AUTOSAR XML (schema 4-2-2)
package /STELLANTIS/EPT/ASWCs
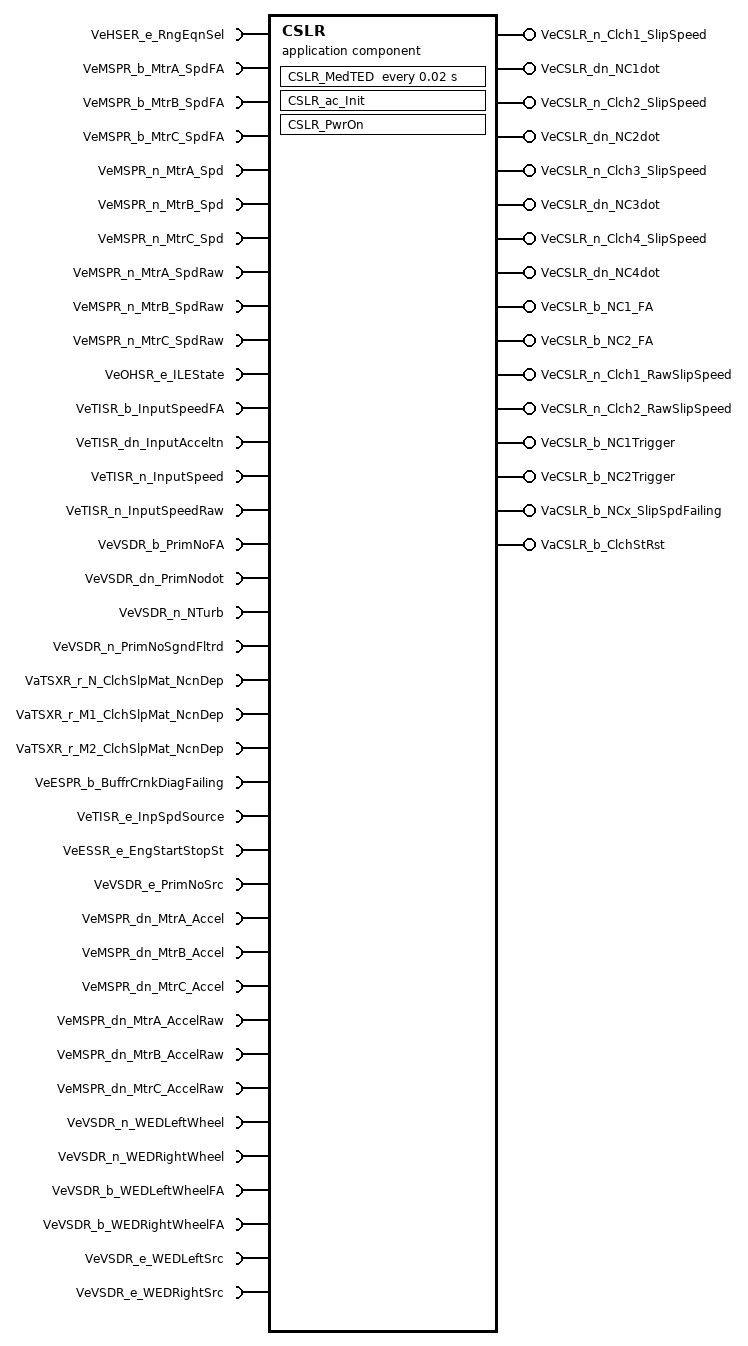
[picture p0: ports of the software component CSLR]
  application sw component type CSLR
    38 x require port:
      VeHSER_e_RngEqnSel: nonqueued-receiver-com-spec{data-element=Value, init-value=CeHSER_e_UseNeutralEqn}, required-interface=VeHSER_e_RngEqnSel
      VeMSPR_b_MtrA_SpdFA: nonqueued-receiver-com-spec{data-element=Value, init-value=0}, required-interface=VeMSPR_b_MtrA_SpdFA
      VeMSPR_b_MtrB_SpdFA: nonqueued-receiver-com-spec{data-element=Value, init-value=0}, required-interface=VeMSPR_b_MtrB_SpdFA
      VeMSPR_b_MtrC_SpdFA: nonqueued-receiver-com-spec{data-element=Value, init-value=0}, required-interface=VeMSPR_b_MtrC_SpdFA
      VeMSPR_n_MtrA_Spd: nonqueued-receiver-com-spec{data-element=Value, init-value=0}, required-interface=VeMSPR_n_MtrA_Spd
      VeMSPR_n_MtrB_Spd: nonqueued-receiver-com-spec{data-element=Value, init-value=0}, required-interface=VeMSPR_n_MtrB_Spd
      VeMSPR_n_MtrC_Spd: nonqueued-receiver-com-spec{data-element=Value, init-value=0}, required-interface=VeMSPR_n_MtrC_Spd
      VeMSPR_n_MtrA_SpdRaw: nonqueued-receiver-com-spec{data-element=Value, init-value=0}, required-interface=VeMSPR_n_MtrA_SpdRaw
      VeMSPR_n_MtrB_SpdRaw: nonqueued-receiver-com-spec{data-element=Value, init-value=0}, required-interface=VeMSPR_n_MtrB_SpdRaw
      VeMSPR_n_MtrC_SpdRaw: nonqueued-receiver-com-spec{data-element=Value, init-value=0}, required-interface=VeMSPR_n_MtrC_SpdRaw
      VeOHSR_e_ILEState: nonqueued-receiver-com-spec{data-element=Value, init-value=CeOHSR_e_NeutralState}, required-interface=VeOHSR_e_ILEState
      VeTISR_b_InputSpeedFA: nonqueued-receiver-com-spec{data-element=Value, init-value=0}, required-interface=VeTISR_b_InputSpeedFA
      VeTISR_dn_InputAcceltn: nonqueued-receiver-com-spec{data-element=Value, init-value=0}, required-interface=VeTISR_dn_InputAcceltn
      VeTISR_n_InputSpeed: nonqueued-receiver-com-spec{data-element=Value, init-value=0}, required-interface=VeTISR_n_InputSpeed
      VeTISR_n_InputSpeedRaw: nonqueued-receiver-com-spec{data-element=Value, init-value=0}, required-interface=VeTISR_n_InputSpeedRaw
      VeVSDR_b_PrimNoFA: nonqueued-receiver-com-spec{data-element=Value, init-value=0}, required-interface=VeVSDR_b_PrimNoFA
      VeVSDR_dn_PrimNodot: nonqueued-receiver-com-spec{data-element=Value, init-value=0}, required-interface=VeVSDR_dn_PrimNodot
      VeVSDR_n_NTurb: nonqueued-receiver-com-spec{data-element=Value, init-value=0}, required-interface=VeVSDR_n_NTurb
      VeVSDR_n_PrimNoSgndFltrd: nonqueued-receiver-com-spec{data-element=Value, init-value=0}, required-interface=VeVSDR_n_PrimNoSgndFltrd
      VaTSXR_r_N_ClchSlpMat_NcnDep: nonqueued-receiver-com-spec{data-element=Value, init-value=32 x 0}, required-interface=VaTSXR_r_N_ClchSlpMat_NcnDep
      VaTSXR_r_M1_ClchSlpMat_NcnDep: nonqueued-receiver-com-spec{data-element=Value, init-value=32 x 0}, required-interface=VaTSXR_r_M1_ClchSlpMat_NcnDep
      VaTSXR_r_M2_ClchSlpMat_NcnDep: nonqueued-receiver-com-spec{data-element=Value, init-value=32 x 0}, required-interface=VaTSXR_r_M2_ClchSlpMat_NcnDep
      VeESPR_b_BuffrCrnkDiagFailing: nonqueued-receiver-com-spec{data-element=Value, init-value=0}, required-interface=VeESPR_b_BuffrCrnkDiagFailing
      VeTISR_e_InpSpdSource: nonqueued-receiver-com-spec{data-element=Value, init-value=CeTISR_e_EngSpeedFromCAN}, required-interface=VeTISR_e_InpSpdSource
      VeESSR_e_EngStartStopSt: nonqueued-receiver-com-spec{data-element=Value, init-value=CeESSR_e_EngOff}, required-interface=VeESSR_e_EngStartStopSt
      VeVSDR_e_PrimNoSrc: nonqueued-receiver-com-spec{data-element=Value, init-value=CeVSDR_e_PrimNoSrcNotAvail}, required-interface=VeVSDR_e_PrimNoSrc
      VeMSPR_dn_MtrA_Accel: nonqueued-receiver-com-spec{data-element=Value, init-value=0}, required-interface=VeMSPR_dn_MtrA_Accel
      VeMSPR_dn_MtrB_Accel: nonqueued-receiver-com-spec{data-element=Value, init-value=0}, required-interface=VeMSPR_dn_MtrB_Accel
      VeMSPR_dn_MtrC_Accel: nonqueued-receiver-com-spec{data-element=Value, init-value=0}, required-interface=VeMSPR_dn_MtrC_Accel
      VeMSPR_dn_MtrA_AccelRaw: nonqueued-receiver-com-spec{data-element=Value, init-value=0}, required-interface=VeMSPR_dn_MtrA_AccelRaw
      VeMSPR_dn_MtrB_AccelRaw: nonqueued-receiver-com-spec{data-element=Value, init-value=0}, required-interface=VeMSPR_dn_MtrB_AccelRaw
      VeMSPR_dn_MtrC_AccelRaw: nonqueued-receiver-com-spec{data-element=Value, init-value=0}, required-interface=VeMSPR_dn_MtrC_AccelRaw
      VeVSDR_n_WEDLeftWheel: nonqueued-receiver-com-spec{data-element=Value, init-value=0}, required-interface=VeVSDR_n_WEDLeftWheel
      VeVSDR_n_WEDRightWheel: nonqueued-receiver-com-spec{data-element=Value, init-value=0}, required-interface=VeVSDR_n_WEDRightWheel
      VeVSDR_b_WEDLeftWheelFA: nonqueued-receiver-com-spec{data-element=Value, init-value=0}, required-interface=VeVSDR_b_WEDLeftWheelFA
      VeVSDR_b_WEDRightWheelFA: nonqueued-receiver-com-spec{data-element=Value, init-value=0}, required-interface=VeVSDR_b_WEDRightWheelFA
      VeVSDR_e_WEDLeftSrc: nonqueued-receiver-com-spec{data-element=Value, init-value=CeVSDR_e_WEDWhlSpdFromFrontWhls}, required-interface=VeVSDR_e_WEDLeftSrc
      VeVSDR_e_WEDRightSrc: nonqueued-receiver-com-spec{data-element=Value, init-value=CeVSDR_e_WEDWhlSpdFromFrontWhls}, required-interface=VeVSDR_e_WEDRightSrc
    16 x provide port:
      VeCSLR_n_Clch1_SlipSpeed: nonqueued-sender-com-spec{data-element=Value, init-value=0}, provided-interface=VeCSLR_n_Clch1_SlipSpeed
      VeCSLR_dn_NC1dot: nonqueued-sender-com-spec{data-element=Value, init-value=0}, provided-interface=VeCSLR_dn_NC1dot
      VeCSLR_n_Clch2_SlipSpeed: nonqueued-sender-com-spec{data-element=Value, init-value=0}, provided-interface=VeCSLR_n_Clch2_SlipSpeed
      VeCSLR_dn_NC2dot: nonqueued-sender-com-spec{data-element=Value, init-value=0}, provided-interface=VeCSLR_dn_NC2dot
      VeCSLR_n_Clch3_SlipSpeed: nonqueued-sender-com-spec{data-element=Value, init-value=0}, provided-interface=VeCSLR_n_Clch3_SlipSpeed
      VeCSLR_dn_NC3dot: nonqueued-sender-com-spec{data-element=Value, init-value=0}, provided-interface=VeCSLR_dn_NC3dot
      VeCSLR_n_Clch4_SlipSpeed: nonqueued-sender-com-spec{data-element=Value, init-value=0}, provided-interface=VeCSLR_n_Clch4_SlipSpeed
      VeCSLR_dn_NC4dot: nonqueued-sender-com-spec{data-element=Value, init-value=0}, provided-interface=VeCSLR_dn_NC4dot
      VeCSLR_b_NC1_FA: nonqueued-sender-com-spec{data-element=Value, init-value=0}, provided-interface=VeCSLR_b_NC1_FA
      VeCSLR_b_NC2_FA: nonqueued-sender-com-spec{data-element=Value, init-value=0}, provided-interface=VeCSLR_b_NC2_FA
      VeCSLR_n_Clch1_RawSlipSpeed: nonqueued-sender-com-spec{data-element=Value, init-value=0}, provided-interface=VeCSLR_n_Clch1_RawSlipSpeed
      VeCSLR_n_Clch2_RawSlipSpeed: nonqueued-sender-com-spec{data-element=Value, init-value=0}, provided-interface=VeCSLR_n_Clch2_RawSlipSpeed
      VeCSLR_b_NC1Trigger: nonqueued-sender-com-spec{data-element=Value, init-value=0}, provided-interface=VeCSLR_b_NC1Trigger
      VeCSLR_b_NC2Trigger: nonqueued-sender-com-spec{data-element=Value, init-value=0}, provided-interface=VeCSLR_b_NC2Trigger
      VaCSLR_b_NCx_SlipSpdFailing: nonqueued-sender-com-spec{data-element=Value, init-value=[0, 0, 0, 0]}, provided-interface=VaCSLR_b_NCx_SlipSpdFailing
      VaCSLR_b_ClchStRst: nonqueued-sender-com-spec{data-element=Value, init-value=[0, 0, 0, 0]}, provided-interface=VaCSLR_b_ClchStRst
    behavior IB_CSLR: data-type-mapping=msADTtoIDTMapping, handle-termination-and-restart=NO-SUPPORT
      timing event Event_MedTED: start-on-event=CSLR_MedTED, period=0.02
      init event Event_CSLR_ac_Init: start-on-event=CSLR_ac_Init
      init event Event_PwrOn: start-on-event=CSLR_PwrOn
      runnable CSLR_ac_Init
        data-send-points:
          access OUT_VaCSLR_b_NCx_SlipSpdFailing_Value: accessed-variable=VaCSLR_b_NCx_SlipSpdFailing.Value
          access OUT_VaCSLR_b_ClchStRst_Value: accessed-variable=VaCSLR_b_ClchStRst.Value
      runnable CSLR_PwrOn
        data-send-points:
          16 x access:
            OUT_VeCSLR_n_Clch1_SlipSpeed_Value: accessed-variable=VeCSLR_n_Clch1_SlipSpeed.Value
            OUT_VeCSLR_dn_NC1dot_Value: accessed-variable=VeCSLR_dn_NC1dot.Value
            OUT_VeCSLR_n_Clch1_RawSlipSpeed_Value: accessed-variable=VeCSLR_n_Clch1_RawSlipSpeed.Value
            OUT_VeCSLR_n_Clch2_RawSlipSpeed_Value: accessed-variable=VeCSLR_n_Clch2_RawSlipSpeed.Value
            OUT_VaCSLR_b_ClchStRst_Value: accessed-variable=VaCSLR_b_ClchStRst.Value
            OUT_VeCSLR_n_Clch2_SlipSpeed_Value: accessed-variable=VeCSLR_n_Clch2_SlipSpeed.Value
            OUT_VeCSLR_b_NC1Trigger_Value: accessed-variable=VeCSLR_b_NC1Trigger.Value
            OUT_VeCSLR_b_NC2Trigger_Value: accessed-variable=VeCSLR_b_NC2Trigger.Value
            OUT_VeCSLR_dn_NC2dot_Value: accessed-variable=VeCSLR_dn_NC2dot.Value
            OUT_VaCSLR_b_NCx_SlipSpdFailing_Value: accessed-variable=VaCSLR_b_NCx_SlipSpdFailing.Value
            OUT_VeCSLR_n_Clch3_SlipSpeed_Value: accessed-variable=VeCSLR_n_Clch3_SlipSpeed.Value
            OUT_VeCSLR_dn_NC3dot_Value: accessed-variable=VeCSLR_dn_NC3dot.Value
            OUT_VeCSLR_n_Clch4_SlipSpeed_Value: accessed-variable=VeCSLR_n_Clch4_SlipSpeed.Value
            OUT_VeCSLR_dn_NC4dot_Value: accessed-variable=VeCSLR_dn_NC4dot.Value
            OUT_VeCSLR_b_NC1_FA_Value: accessed-variable=VeCSLR_b_NC1_FA.Value
            OUT_VeCSLR_b_NC2_FA_Value: accessed-variable=VeCSLR_b_NC2_FA.Value
      runnable CSLR_MedTED
        data-receive-point-by-arguments:
          36 x access:
            IN_VaTSXR_r_M1_ClchSlpMat_NcnDep_Value: accessed-variable=VaTSXR_r_M1_ClchSlpMat_NcnDep.Value
            IN_VaTSXR_r_M2_ClchSlpMat_NcnDep_Value: accessed-variable=VaTSXR_r_M2_ClchSlpMat_NcnDep.Value
            IN_VaTSXR_r_N_ClchSlpMat_NcnDep_Value: accessed-variable=VaTSXR_r_N_ClchSlpMat_NcnDep.Value
            IN_VeESPR_b_BuffrCrnkDiagFailing_Value: accessed-variable=VeESPR_b_BuffrCrnkDiagFailing.Value
            IN_VeESSR_e_EngStartStopSt_Value: accessed-variable=VeESSR_e_EngStartStopSt.Value
            IN_VeHSER_e_RngEqnSel_Value: accessed-variable=VeHSER_e_RngEqnSel.Value
            IN_VeMSPR_b_MtrA_SpdFA_Value: accessed-variable=VeMSPR_b_MtrA_SpdFA.Value
            IN_VeMSPR_b_MtrB_SpdFA_Value: accessed-variable=VeMSPR_b_MtrB_SpdFA.Value
            IN_VeMSPR_b_MtrC_SpdFA_Value: accessed-variable=VeMSPR_b_MtrC_SpdFA.Value
            IN_VeMSPR_dn_MtrA_Accel_Value: accessed-variable=VeMSPR_dn_MtrA_Accel.Value
            IN_VeMSPR_dn_MtrA_AccelRaw_Value: accessed-variable=VeMSPR_dn_MtrA_AccelRaw.Value
            IN_VeMSPR_dn_MtrB_Accel_Value: accessed-variable=VeMSPR_dn_MtrB_Accel.Value
            IN_VeMSPR_dn_MtrB_AccelRaw_Value: accessed-variable=VeMSPR_dn_MtrB_AccelRaw.Value
            IN_VeMSPR_dn_MtrC_Accel_Value: accessed-variable=VeMSPR_dn_MtrC_Accel.Value
            IN_VeMSPR_dn_MtrC_AccelRaw_Value: accessed-variable=VeMSPR_dn_MtrC_AccelRaw.Value
            IN_VeMSPR_n_MtrA_Spd_Value: accessed-variable=VeMSPR_n_MtrA_Spd.Value
            IN_VeMSPR_n_MtrA_SpdRaw_Value: accessed-variable=VeMSPR_n_MtrA_SpdRaw.Value
            IN_VeMSPR_n_MtrB_Spd_Value: accessed-variable=VeMSPR_n_MtrB_Spd.Value
            IN_VeMSPR_n_MtrB_SpdRaw_Value: accessed-variable=VeMSPR_n_MtrB_SpdRaw.Value
            IN_VeMSPR_n_MtrC_Spd_Value: accessed-variable=VeMSPR_n_MtrC_Spd.Value
            IN_VeMSPR_n_MtrC_SpdRaw_Value: accessed-variable=VeMSPR_n_MtrC_SpdRaw.Value
            IN_VeOHSR_e_ILEState_Value: accessed-variable=VeOHSR_e_ILEState.Value
            IN_VeTISR_b_InputSpeedFA_Value: accessed-variable=VeTISR_b_InputSpeedFA.Value
            IN_VeTISR_dn_InputAcceltn_Value: accessed-variable=VeTISR_dn_InputAcceltn.Value
            IN_VeTISR_e_InpSpdSource_Value: accessed-variable=VeTISR_e_InpSpdSource.Value
            IN_VeTISR_n_InputSpeed_Value: accessed-variable=VeTISR_n_InputSpeed.Value
            IN_VeTISR_n_InputSpeedRaw_Value: accessed-variable=VeTISR_n_InputSpeedRaw.Value
            IN_VeVSDR_b_PrimNoFA_Value: accessed-variable=VeVSDR_b_PrimNoFA.Value
            IN_VeVSDR_b_WEDLeftWheelFA_Value: accessed-variable=VeVSDR_b_WEDLeftWheelFA.Value
            IN_VeVSDR_b_WEDRightWheelFA_Value: accessed-variable=VeVSDR_b_WEDRightWheelFA.Value
            IN_VeVSDR_dn_PrimNodot_Value: accessed-variable=VeVSDR_dn_PrimNodot.Value
            IN_VeVSDR_e_PrimNoSrc_Value: accessed-variable=VeVSDR_e_PrimNoSrc.Value
            IN_VeVSDR_n_NTurb_Value: accessed-variable=VeVSDR_n_NTurb.Value
            IN_VeVSDR_n_PrimNoSgndFltrd_Value: accessed-variable=VeVSDR_n_PrimNoSgndFltrd.Value
            IN_VeVSDR_n_WEDLeftWheel_Value: accessed-variable=VeVSDR_n_WEDLeftWheel.Value
            IN_VeVSDR_n_WEDRightWheel_Value: accessed-variable=VeVSDR_n_WEDRightWheel.Value
        data-send-points:
          16 x access:
            OUT_VeCSLR_n_Clch1_SlipSpeed_Value: accessed-variable=VeCSLR_n_Clch1_SlipSpeed.Value
            OUT_VeCSLR_dn_NC1dot_Value: accessed-variable=VeCSLR_dn_NC1dot.Value
            OUT_VeCSLR_n_Clch1_RawSlipSpeed_Value: accessed-variable=VeCSLR_n_Clch1_RawSlipSpeed.Value
            OUT_VeCSLR_n_Clch2_RawSlipSpeed_Value: accessed-variable=VeCSLR_n_Clch2_RawSlipSpeed.Value
            OUT_VaCSLR_b_ClchStRst_Value: accessed-variable=VaCSLR_b_ClchStRst.Value
            OUT_VeCSLR_n_Clch2_SlipSpeed_Value: accessed-variable=VeCSLR_n_Clch2_SlipSpeed.Value
            OUT_VeCSLR_b_NC1Trigger_Value: accessed-variable=VeCSLR_b_NC1Trigger.Value
            OUT_VeCSLR_b_NC2Trigger_Value: accessed-variable=VeCSLR_b_NC2Trigger.Value
            OUT_VeCSLR_dn_NC2dot_Value: accessed-variable=VeCSLR_dn_NC2dot.Value
            OUT_VeCSLR_n_Clch3_SlipSpeed_Value: accessed-variable=VeCSLR_n_Clch3_SlipSpeed.Value
            OUT_VeCSLR_dn_NC3dot_Value: accessed-variable=VeCSLR_dn_NC3dot.Value
            OUT_VeCSLR_n_Clch4_SlipSpeed_Value: accessed-variable=VeCSLR_n_Clch4_SlipSpeed.Value
            OUT_VeCSLR_dn_NC4dot_Value: accessed-variable=VeCSLR_dn_NC4dot.Value
            OUT_VeCSLR_b_NC1_FA_Value: accessed-variable=VeCSLR_b_NC1_FA.Value
            OUT_VeCSLR_b_NC2_FA_Value: accessed-variable=VeCSLR_b_NC2_FA.Value
            OUT_VaCSLR_b_NCx_SlipSpdFailing_Value: accessed-variable=VaCSLR_b_NCx_SlipSpdFailing.Value
      6 x variation point proxy, all with category=CONDITION:
        Variant_CSLC_ClcStRstTrggr: condition-access=1
        Variant_CSLR_C1SlipActv: condition-access=0
        Variant_CSLR_C2SlipActv: condition-access=1
        Variant_CSLR_C3SlipActv: condition-access=0
        Variant_CSLR_C4SlipActv: condition-access=0
        Variant_CSLR_EnblNCxFlng_BffrCrnk: condition-access=0
